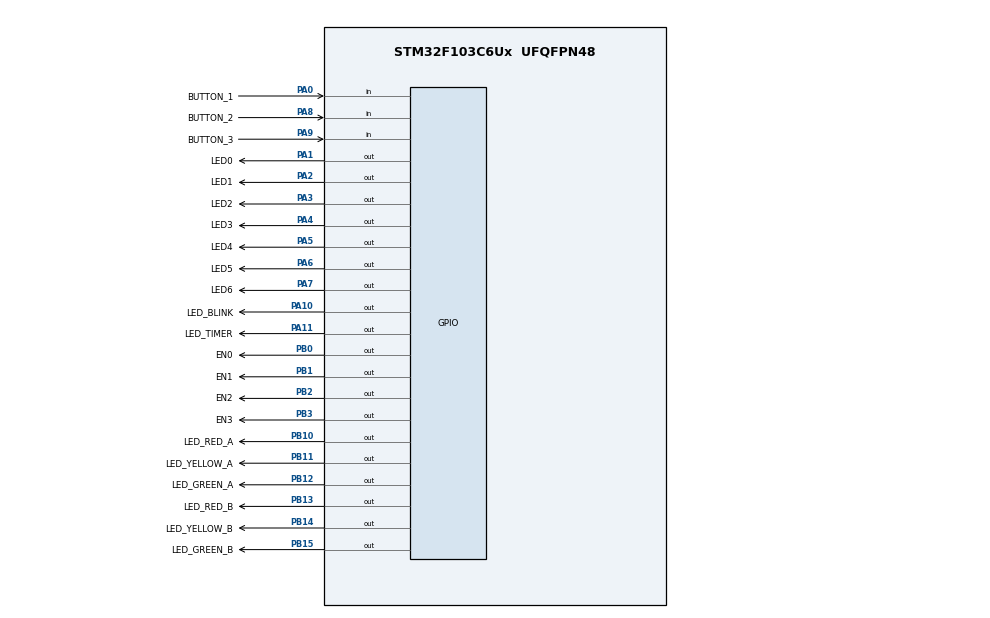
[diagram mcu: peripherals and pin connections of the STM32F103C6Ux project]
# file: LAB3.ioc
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Mcu.Family=STM32F1
Mcu.Name=STM32F103C6Ux
Mcu.Package=UFQFPN48
NVIC.PriorityGroup=NVIC_PRIORITYGROUP_4
NVIC.TIM2_IRQn=true\:0\:0\:false\:false\:true\:true\:true
PA0-WKUP.GPIO_Label=BUTTON_1
PA0-WKUP.Signal=GPIO_Input
PA1.GPIO_Label=LED0
PA1.GPIO_PuPd=GPIO_NOPULL
PA1.Signal=GPIO_Output
PA10.GPIO_Label=LED_BLINK
PA10.Signal=GPIO_Output
PA11.GPIO_Label=LED_TIMER
PA11.Signal=GPIO_Output
PA2.GPIO_Label=LED1
PA2.GPIO_PuPd=GPIO_NOPULL
PA2.Signal=GPIO_Output
PA3.GPIO_Label=LED2
PA3.GPIO_PuPd=GPIO_NOPULL
PA3.Signal=GPIO_Output
PA4.GPIO_Label=LED3
PA4.GPIO_PuPd=GPIO_NOPULL
PA4.Signal=GPIO_Output
PA5.GPIO_Label=LED4
PA5.GPIO_PuPd=GPIO_NOPULL
PA5.Signal=GPIO_Output
PA6.GPIO_Label=LED5
PA6.GPIO_PuPd=GPIO_NOPULL
PA6.Signal=GPIO_Output
PA7.GPIO_Label=LED6
PA7.GPIO_PuPd=GPIO_NOPULL
PA7.Signal=GPIO_Output
PA8.GPIO_Label=BUTTON_2
PA8.Signal=GPIO_Input
PA9.GPIO_Label=BUTTON_3
PA9.Signal=GPIO_Input
PB0.GPIO_Label=EN0
PB0.Signal=GPIO_Output
PB1.GPIO_Label=EN1
PB1.Signal=GPIO_Output
PB10.GPIO_Label=LED_RED_A
PB10.Signal=GPIO_Output
PB11.GPIO_Label=LED_YELLOW_A
PB11.Signal=GPIO_Output
PB12.GPIO_Label=LED_GREEN_A
PB12.Signal=GPIO_Output
PB13.GPIO_Label=LED_RED_B
PB13.Signal=GPIO_Output
PB14.GPIO_Label=LED_YELLOW_B
PB14.Signal=GPIO_Output
PB15.GPIO_Label=LED_GREEN_B
PB15.Signal=GPIO_Output
PB2.GPIO_Label=EN2
PB2.Signal=GPIO_Output
PB3.GPIO_Label=EN3
PB3.Signal=GPIO_Output
ProjectManager.HeapSize=0x200
ProjectManager.StackSize=0x400
ProjectManager.TargetToolchain=STM32CubeIDE
RCC.APB1Freq_Value=8000000
RCC.APB2Freq_Value=8000000
TIM2.Period=9
TIM2.Prescaler=7999
VP_SYS_VS_ND.Mode=No_Debug
VP_TIM2_VS_ClockSourceINT.Mode=Internal
board=custom

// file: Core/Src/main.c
/* USER CODE BEGIN Header */
/**
  ******************************************************************************
  * @file           : main.c
  * @brief          : Main program body
  ******************************************************************************
  * @attention
  *
  * <h2><center>&copy; Copyright (c) 2025 STMicroelectronics.
  * All rights reserved.</center></h2>
  *
  * This software component is licensed by ST under BSD 3-Clause license,
  * the "License"; You may not use this file except in compliance with the
  * License. You may obtain a copy of the License at:
  *                        opensource.org/licenses/BSD-3-Clause
  *
  ******************************************************************************
  */
/* USER CODE END Header */
#include "main.h"
#include "automatic.h"
#include "manual.h"
#include "scheduler.h"

TIM_HandleTypeDef htim2;

void SystemClock_Config(void);
static void MX_GPIO_Init(void);
static void MX_TIM2_Init(void);

void led1test(){
	  HAL_GPIO_TogglePin(LED_BLINK_GPIO_Port, LED_BLINK_Pin);
  }
void task_update_led7seg(void) {
    printled();
}
void task_getkeyinput(void){
	getKeyInput();
}
void task_timer_run(void){
	timer_run();
}
void task_fsm_machine(void){
	if (isbuttonpressed(0) == 1) {
		  		  if (status == INIT || (status >= AUTO_RED_GREEN && status <= AUTO_YELLOW_RED)) {
		  			  status = MAN_RED;
		  			  turnoffled();
		  			  setTimer(4, 500);
		  			  updateLEDBuffer(2, temp_red);
		  		  }
		  		  else if (status == MAN_RED) {
		  			  status = MAN_YELLOW;
		  			  turnoffled();
		  			  setTimer(4, 500);
		  			  updateLEDBuffer(3, temp_yellow);
		  		  }
		  		  else if (status == MAN_YELLOW) {
		  			  status = MAN_GREEN;
		  			  turnoffled();
		  			  setTimer(4, 500);
		  			  updateLEDBuffer(4, temp_green);
		  		  }
		  		  else if (status == MAN_GREEN){

		  			  status = INIT;
		  			  turnoffled();
		  		  }
		  	  }
		  	  if (status == INIT || (status >= AUTO_RED_GREEN && status <= AUTO_YELLOW_RED)){
		  		  fsm_automatic_run();
		  	  }
		  	  else if (status >= MAN_RED && status <= MAN_GREEN){
		  		  fsm_manual_run();
		  	  }
}
int main(void)
{

  /* MCU Configuration--------------------------------------------------------*/

  /* Reset of all peripherals, Initializes the Flash interface and the Systick. */
  HAL_Init();

  /* Configure the system clock */
  SystemClock_Config();

  /* Initialize all configured peripherals */
  MX_GPIO_Init();
  MX_TIM2_Init();
  /* USER CODE BEGIN 2 */
  HAL_TIM_Base_Start_IT(&htim2);
  SCH_Init();
  /* USER CODE END 2 */

  /* Infinite loop */
  /* USER CODE BEGIN WHILE */
  setTimer(0, 1000);
  setTimer(1,5000);
  setTimer(3,120);
  updateLEDBuffer(time_red,time_green);

  SCH_Add_Task(task_update_led7seg,0,17);
  SCH_Add_Task(task_getkeyinput, 0, 1);
  SCH_Add_Task(led1test, 0, 100);
  SCH_Add_Task(task_timer_run, 0, 1);
  SCH_Add_Task(task_fsm_machine, 1, 10);
  while (1)
  {
	  SCH_Dispatch_Tasks();

    /* USER CODE END WHILE */

  }
}

void SystemClock_Config(void)
{
  RCC_OscInitTypeDef RCC_OscInitStruct = {0};
  RCC_ClkInitTypeDef RCC_ClkInitStruct = {0};

  /** Initializes the RCC Oscillators according to the specified parameters
  * in the RCC_OscInitTypeDef structure.
  */
  RCC_OscInitStruct.OscillatorType = RCC_OSCILLATORTYPE_HSI;
  RCC_OscInitStruct.HSIState = RCC_HSI_ON;
  RCC_OscInitStruct.HSICalibrationValue = RCC_HSICALIBRATION_DEFAULT;
  RCC_OscInitStruct.PLL.PLLState = RCC_PLL_NONE;
  if (HAL_RCC_OscConfig(&RCC_OscInitStruct) != HAL_OK)
  {
    Error_Handler();
  }
  /** Initializes the CPU, AHB and APB buses clocks
  */
  RCC_ClkInitStruct.ClockType = RCC_CLOCKTYPE_HCLK|RCC_CLOCKTYPE_SYSCLK
                              |RCC_CLOCKTYPE_PCLK1|RCC_CLOCKTYPE_PCLK2;
  RCC_ClkInitStruct.SYSCLKSource = RCC_SYSCLKSOURCE_HSI;
  RCC_ClkInitStruct.AHBCLKDivider = RCC_SYSCLK_DIV1;
  RCC_ClkInitStruct.APB1CLKDivider = RCC_HCLK_DIV1;
  RCC_ClkInitStruct.APB2CLKDivider = RCC_HCLK_DIV1;

  if (HAL_RCC_ClockConfig(&RCC_ClkInitStruct, FLASH_LATENCY_0) != HAL_OK)
  {
    Error_Handler();
  }
}

static void MX_TIM2_Init(void)
{

  TIM_ClockConfigTypeDef sClockSourceConfig = {0};
  TIM_MasterConfigTypeDef sMasterConfig = {0};

  htim2.Instance = TIM2;
  htim2.Init.Prescaler = 7999;
  htim2.Init.CounterMode = TIM_COUNTERMODE_UP;
  htim2.Init.Period = 9;
  htim2.Init.ClockDivision = TIM_CLOCKDIVISION_DIV1;
  htim2.Init.AutoReloadPreload = TIM_AUTORELOAD_PRELOAD_DISABLE;
  if (HAL_TIM_Base_Init(&htim2) != HAL_OK)
  {
    Error_Handler();
  }
  sClockSourceConfig.ClockSource = TIM_CLOCKSOURCE_INTERNAL;
  if (HAL_TIM_ConfigClockSource(&htim2, &sClockSourceConfig) != HAL_OK)
  {
    Error_Handler();
  }
  sMasterConfig.MasterOutputTrigger = TIM_TRGO_RESET;
  sMasterConfig.MasterSlaveMode = TIM_MASTERSLAVEMODE_DISABLE;
  if (HAL_TIMEx_MasterConfigSynchronization(&htim2, &sMasterConfig) != HAL_OK)
  {
    Error_Handler();
  }

}

static void MX_GPIO_Init(void)
{
  GPIO_InitTypeDef GPIO_InitStruct = {0};

  /* GPIO Ports Clock Enable */
  __HAL_RCC_GPIOA_CLK_ENABLE();
  __HAL_RCC_GPIOB_CLK_ENABLE();

  /*Configure GPIO pin Output Level */
  HAL_GPIO_WritePin(GPIOA, LED0_Pin|LED1_Pin|LED2_Pin|LED3_Pin
                          |LED4_Pin|LED5_Pin|LED6_Pin|LED_BLINK_Pin, GPIO_PIN_SET);

  /*Configure GPIO pin Output Level */
  HAL_GPIO_WritePin(GPIOB, EN0_Pin|EN1_Pin|EN2_Pin|LED_RED_A_Pin
                          |LED_YELLOW_A_Pin|LED_GREEN_A_Pin|LED_RED_B_Pin|LED_YELLOW_B_Pin
                          |LED_GREEN_B_Pin|EN3_Pin, GPIO_PIN_SET);

  /*Configure GPIO pins : BUTTON_1_Pin BUTTON_2_Pin BUTTON_3_Pin */
  GPIO_InitStruct.Pin = BUTTON_1_Pin|BUTTON_2_Pin|BUTTON_3_Pin;
  GPIO_InitStruct.Mode = GPIO_MODE_INPUT;
  GPIO_InitStruct.Pull = GPIO_NOPULL;
  HAL_GPIO_Init(GPIOA, &GPIO_InitStruct);

  /*Configure GPIO pins : LED0_Pin LED1_Pin LED2_Pin LED3_Pin
                           LED4_Pin LED5_Pin LED6_Pin LED_BLINK_Pin */
  GPIO_InitStruct.Pin = LED0_Pin|LED1_Pin|LED2_Pin|LED3_Pin
                          |LED4_Pin|LED5_Pin|LED6_Pin|LED_BLINK_Pin;
  GPIO_InitStruct.Mode = GPIO_MODE_OUTPUT_PP;
  GPIO_InitStruct.Pull = GPIO_NOPULL;
  GPIO_InitStruct.Speed = GPIO_SPEED_FREQ_LOW;
  HAL_GPIO_Init(GPIOA, &GPIO_InitStruct);

  /*Configure GPIO pins : EN0_Pin EN1_Pin EN2_Pin LED_RED_A_Pin
                           LED_YELLOW_A_Pin LED_GREEN_A_Pin LED_RED_B_Pin LED_YELLOW_B_Pin
                           LED_GREEN_B_Pin EN3_Pin */
  GPIO_InitStruct.Pin = EN0_Pin|EN1_Pin|EN2_Pin|LED_RED_A_Pin
                          |LED_YELLOW_A_Pin|LED_GREEN_A_Pin|LED_RED_B_Pin|LED_YELLOW_B_Pin
                          |LED_GREEN_B_Pin|EN3_Pin;
  GPIO_InitStruct.Mode = GPIO_MODE_OUTPUT_PP;
  GPIO_InitStruct.Pull = GPIO_NOPULL;
  GPIO_InitStruct.Speed = GPIO_SPEED_FREQ_LOW;
  HAL_GPIO_Init(GPIOB, &GPIO_InitStruct);

}

void Error_Handler(void)
{
  __disable_irq();
  while (1)
  {
  }
}

/************************ (C) COPYRIGHT STMicroelectronics *****END OF FILE****/
